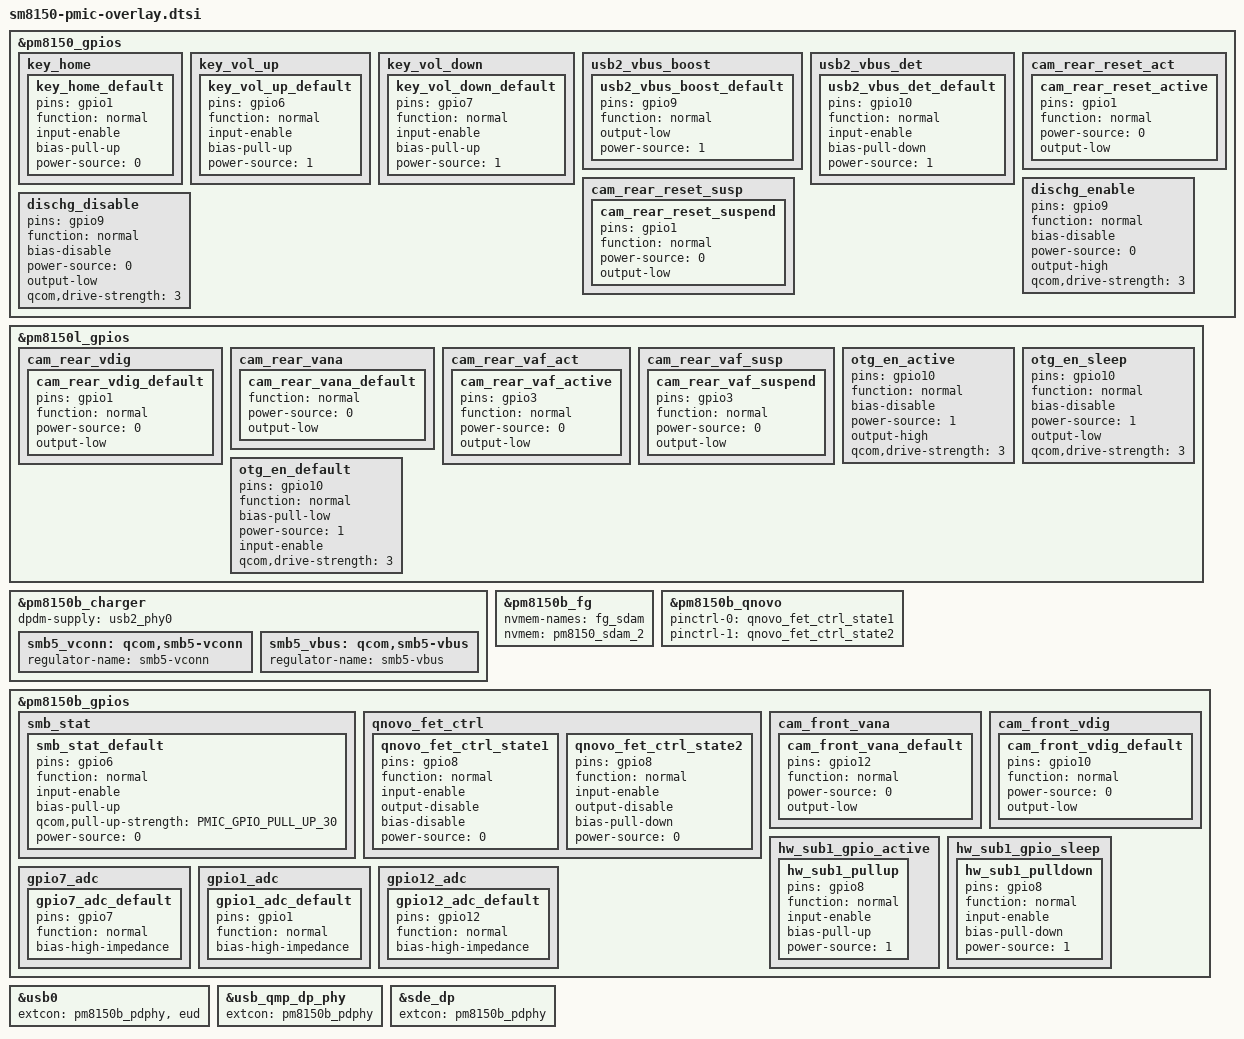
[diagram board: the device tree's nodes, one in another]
/*
 * Copyright (c) 2017-2019, The Linux Foundation. All rights reserved.
 *
 * This program is free software; you can redistribute it and/or modify
 * it under the terms of the GNU General Public License version 2 and
 * only version 2 as published by the Free Software Foundation.
 *
 * This program is distributed in the hope that it will be useful,
 * but WITHOUT ANY WARRANTY; without even the implied warranty of
 * MERCHANTABILITY or FITNESS FOR A PARTICULAR PURPOSE.  See the
 * GNU General Public License for more details.
 */

#include "pm8150.dtsi"
#include "pm8150b.dtsi"
#include "pm8150l.dtsi"
#include <dt-bindings/pinctrl/qcom,pmic-gpio.h>

/* PMIC GPIO pin control configurations: */
&pm8150_gpios {
	key_home {
		key_home_default: key_home_default {
			pins = "gpio1";
			function = "normal";
			input-enable;
			bias-pull-up;
			power-source = <0>;
		};
	};

	key_vol_up {
		key_vol_up_default: key_vol_up_default {
			pins = "gpio6";
			function = "normal";
			input-enable;
			bias-pull-up;
			power-source = <1>;
		};
	};

	/*ifdef VENDOR_EDIT*/
	key_vol_down {
		key_vol_down_default: key_vol_down_default {
			pins = "gpio7";
			function = "normal";
			input-enable;
			bias-pull-up;
			power-source = <1>;
		};
	};
	/*endif*/

	usb2_vbus_boost {
		usb2_vbus_boost_default: usb2_vbus_boost_default {
			pins = "gpio9";
			function = "normal";
			output-low;
			power-source = <1>;	/* 1.8V input supply */
		};
	};

	usb2_vbus_det {
		usb2_vbus_det_default: usb2_vbus_det_default {
			pins = "gpio10";
			function = "normal";
			input-enable;
			bias-pull-down;
			power-source = <1>;	/* 1.8V input supply */
		};
	};
/*ifdef VENDOR_EDIT*/
	cam_rear_reset_act {
		cam_rear_reset_active: cam_rear_reset_active {
			pins = "gpio1";
			function = "normal";
			power-source = <0>;
			output-low;
		};
	};
	cam_rear_reset_susp {
		cam_rear_reset_suspend: cam_rear_reset_suspend {
			pins = "gpio1";
			function = "normal";
			power-source = <0>;
			output-low;
		};
	};
/*endif*/
};

&pm8150l_gpios {
	/* #ifdef VENDOR_EDIT */
	/*
	cam_sensor_eldo4 {
		cam_sensor_eldo4_default: cam_sensor_eldo4_default {
			pins = "gpio3";
			function = "normal";
			power-source = <0>;
			output-low;
		};
	};

	cam_sensor_eldo3 {
		cam_sensor_eldo3_default: cam_sensor_eldo3_default {
			pins = "gpio4";
			function = "normal";
			power-source = <0>;
			output-low;
		};
	};
	*/
	/* #else */
	cam_rear_vdig {
		cam_rear_vdig_default: cam_rear_vdig_default {
			pins = "gpio1";
			function = "normal";
			power-source = <0>;
			output-low;
		};
	};

	cam_rear_vana {
		cam_rear_vana_default: cam_rear_vana_default {
		/*#ifdef VENDOR_EDIT*/
		//	pins = "gpio4";
		/*#endif*/
			function = "normal";
			power-source = <0>;
			output-low;
		};
	};
	cam_rear_vaf_act {
		cam_rear_vaf_active: cam_rear_vaf_active {
			pins = "gpio3";
			function = "normal";
			power-source = <0>;
			output-low;
		};
	};
	cam_rear_vaf_susp {
		cam_rear_vaf_suspend: cam_rear_vaf_suspend {
			pins = "gpio3";
			function = "normal";
			power-source = <0>;
			output-low;
		};
	};
	/* #endif */
};

&pm8150b_charger {
	dpdm-supply = <&usb2_phy0>;
	smb5_vconn: qcom,smb5-vconn {
		regulator-name = "smb5-vconn";
	};
	smb5_vbus: qcom,smb5-vbus {
		regulator-name = "smb5-vbus";
	};
};

&pm8150b_fg {
	nvmem-names = "fg_sdam";
	nvmem = <&pm8150_sdam_2>;
};

&pm8150b_qnovo {
	pinctrl-names = "q_state1", "q_state2";
	pinctrl-0 = <&qnovo_fet_ctrl_state1>;
	pinctrl-1 = <&qnovo_fet_ctrl_state2>;
};

&pm8150b_gpios {
	smb_stat {
		smb_stat_default: smb_stat_default {
			pins = "gpio6";
			function = "normal";
			input-enable;
			bias-pull-up;
			qcom,pull-up-strength = <PMIC_GPIO_PULL_UP_30>;
			power-source = <0>;
		};
	};

	qnovo_fet_ctrl {
		qnovo_fet_ctrl_state1: qnovo_fet_ctrl_state1 {
			pins = "gpio8";
			function = "normal";
			input-enable;
			output-disable;
			bias-disable;
			power-source = <0>;
		};

		qnovo_fet_ctrl_state2: qnovo_fet_ctrl_state2 {
			pins = "gpio8";
			function = "normal";
			input-enable;
			output-disable;
			bias-pull-down;
			power-source = <0>;
		};
	};
	/*ifdef VENDOR_EDIT*/
	cam_front_vana {
		cam_front_vana_default: cam_front_vana_default {
			pins = "gpio12";
			function = "normal";
			power-source = <0>;
			output-low;
		};
	};
	cam_front_vdig {
		cam_front_vdig_default: cam_front_vdig_default {
			pins = "gpio10";
			function = "normal";
			power-source = <0>;
			output-low;
		};
	};
	/*#endif*/
	/*ifdef OPLUS_FEATURE_BASIC*/
	hw_sub1_gpio_active {
		hw_sub1_pullup: hw_sub1_pullup {
			pins = "gpio8";
			function = "normal";
			input-enable;
			bias-pull-up;
			power-source = <1>;
		};
	};

	hw_sub1_gpio_sleep {
		hw_sub1_pulldown: hw_sub1_pulldown {
			pins = "gpio8";
			function = "normal";
			input-enable;
			bias-pull-down;
			power-source = <1>;
		};
	};
	/*endif*/

};

&usb0 {
	extcon = <&pm8150b_pdphy>, <&eud>;
};

&usb_qmp_dp_phy {
	extcon = <&pm8150b_pdphy>;
};

&sde_dp {
	extcon = <&pm8150b_pdphy>;
};

&pm8150b_gpios {
    gpio7_adc {
        gpio7_adc_default: gpio7_adc_default {
        pins = "gpio7"; /* GPIO 7 */
        function = "normal"; /* normal */
        bias-high-impedance; /* DISABLE GPIO7 for ADC*/
        };
    };
    gpio1_adc {
        gpio1_adc_default: gpio1_adc_default {
        pins = "gpio1"; /* GPIO 1 */
        function = "normal"; /* normal */
        bias-high-impedance; /* DISABLE GPIO1 for ADC*/
        };
    };
    gpio12_adc {
        gpio12_adc_default: gpio12_adc_default {
        pins = "gpio12"; /* GPIO 12 */
        function = "normal"; /* normal */
        bias-high-impedance; /* DISABLE GPIO1 for ADC*/
        };
    };
};

&pm8150_gpios {
	dischg_enable: dischg_enable {
		pins = "gpio9"; /* GPIO 9 */
		function = "normal"; /* normal */
		bias-disable; //No Pull
		power-source = <0>;//VIN0 3.3
		output-high; //digital output, no invert
		qcom,drive-strength = <3>; //LOW strength
		//drive-push-pull;//CMOS
	};

	dischg_disable: dischg_disable {
		pins = "gpio9"; /* GPIO 9 */
		function = "normal"; /* normal */
		bias-disable; //No Pull
		power-source = <0>;//VIN0 3.3
		output-low; //digital output, no invert
		qcom,drive-strength = <3>; //LOW strength
		//drive-push-pull;//CMOS
	};
};

&pm8150l_gpios {
	otg_en_active: otg_en_active {
		pins = "gpio10"; /* GPIO 10 */
		function = "normal"; /* normal */
		bias-disable; //No Pull
		power-source = <1>;//VIN1 1.8
		output-high; //digital output, no invert
		qcom,drive-strength = <3>; //LOW strength
	//drive-push-pull;//CMOS
	};
	otg_en_sleep: otg_en_sleep {
		pins = "gpio10"; /* GPIO 10 */
		function = "normal"; /* normal */
		bias-disable; //No Pull
		power-source = <1>;//VIN1 1.8
		output-low; //digital output, no invert
		qcom,drive-strength = <3>; //LOW strength
		//drive-push-pull;//CMOS
	};
	otg_en_default: otg_en_default {
		pins = "gpio10"; /* GPIO 10 */
		function = "normal"; /* normal */
		bias-pull-low; // Pull down
		power-source = <1>;//VIN1 1.8
		input-enable; //digital output, no invert
		qcom,drive-strength = <3>; //LOW strength
		//drive-push-pull;//CMOS
	};
};
//#endif
